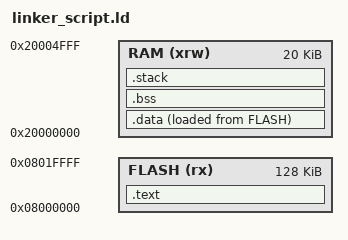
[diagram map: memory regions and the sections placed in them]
OUTPUT_FORMAT("elf32-littlearm")
ENTRY(Reset_Handler)

MEMORY
{
    FLASH (rx) : ORIGIN = 0x08000000, LENGTH = 128K
    RAM (xrw)  : ORIGIN = 0x20000000, LENGTH = 20K
}

SECTIONS
{
    .text : {
        KEEP(*(.isr_vector))    /* Interrupt vector table */
        *(.text*)
        *(.rodata*)
        . = ALIGN(4);
    } > FLASH

    _sidata = LOADADDR(.data);

    .data : {
        . = ALIGN(4);
        _sdata = .;
        *(.data*)
        . = ALIGN(4);
        _edata = .;
    } > RAM AT > FLASH

    .bss : {
        . = ALIGN(4);
        _sbss = .;
        *(.bss*)
        *(COMMON)
        . = ALIGN(4);
        _ebss = .;
    } > RAM

    /* Stack and heap sections if needed */
    .stack : {
        . = ALIGN(8);
        . = . + 0x1000;    /* 4KB of stack */
        . = ALIGN(8);
    } > RAM
}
